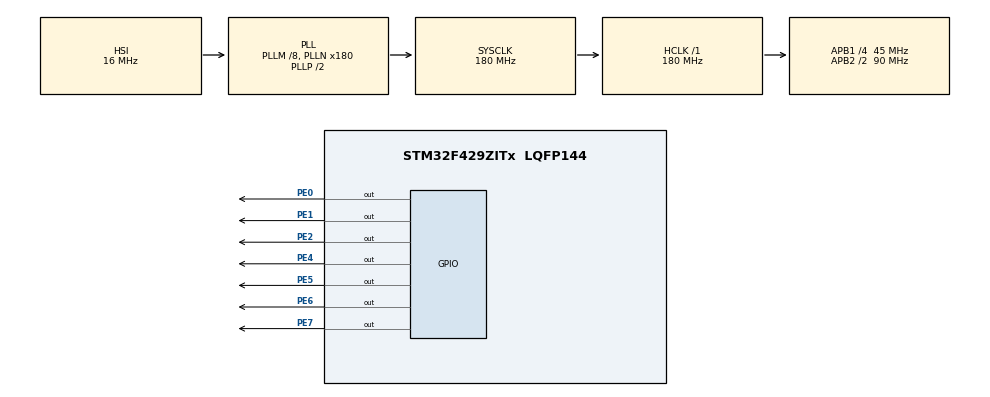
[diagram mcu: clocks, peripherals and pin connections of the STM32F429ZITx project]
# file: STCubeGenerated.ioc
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Mcu.Family=STM32F4
Mcu.Name=STM32F429ZITx
Mcu.Package=LQFP144
NVIC.PriorityGroup=NVIC_PRIORITYGROUP_4
PE0.Signal=GPIO_Output
PE1.Signal=GPIO_Output
PE2.Signal=GPIO_Output
PE4.Signal=GPIO_Output
PE5.Signal=GPIO_Output
PE6.Signal=GPIO_Output
PE7.Signal=GPIO_Output
PH0/OSC_IN.Mode=HSE-External-Oscillator
PH0/OSC_IN.Signal=RCC_OSC_IN
PH1/OSC_OUT.Mode=HSE-External-Oscillator
PH1/OSC_OUT.Signal=RCC_OSC_OUT
ProjectManager.HeapSize=0x200
ProjectManager.StackSize=0x400
ProjectManager.TargetToolchain=MDK-ARM V5
RCC.48MHZClocksFreq_Value=90000000
RCC.AHBFreq_Value=180000000
RCC.APB1CLKDivider=RCC_HCLK_DIV4
RCC.APB1Freq_Value=45000000
RCC.APB1TimFreq_Value=90000000
RCC.APB2CLKDivider=RCC_HCLK_DIV2
RCC.APB2Freq_Value=90000000
RCC.APB2TimFreq_Value=180000000
RCC.CortexFreq_Value=180000000
RCC.HCLKFreq_Value=180000000
RCC.HSE_VALUE=25000000
RCC.HSI_VALUE=16000000
RCC.LSE_VALUE=32768
RCC.PLLM=8
RCC.PLLN=180
RCC.SYSCLKFreq_VALUE=180000000
RCC.SYSCLKSource=RCC_SYSCLKSOURCE_PLLCLK
RCC.VCOOutputFreq_Value=360000000
board=custom

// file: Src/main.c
/* USER CODE BEGIN Header */
/**
  ******************************************************************************
  * @file           : main.c
  * @brief          : Main program body
  ******************************************************************************
  * @attention
  *
  * <h2><center>&copy; Copyright (c) 2019 STMicroelectronics.
  * All rights reserved.</center></h2>
  *
  * This software component is licensed by ST under BSD 3-Clause license,
  * the "License"; You may not use this file except in compliance with the
  * License. You may obtain a copy of the License at:
  *                        opensource.org/licenses/BSD-3-Clause
  *
  ******************************************************************************
  */
/* USER CODE END Header */

#include "main.h"

/* USER CODE BEGIN Includes */
#include "STM_LCD16X2.h"
/* USER CODE END Includes */

void SystemClock_Config(void);
static void MX_GPIO_Init(void);

int main(void)
{

  /* MCU Configuration--------------------------------------------------------*/

  /* Reset of all peripherals, Initializes the Flash interface and the Systick. */
  HAL_Init();

  /* Configure the system clock */
  SystemClock_Config();

  /* Initialize all configured peripherals */
  MX_GPIO_Init();
  /* USER CODE BEGIN 2 */
	LCD1602_Begin4BIT(RS_GPIO_Port, RS_Pin, E_Pin, D4_GPIO_Port, D4_Pin, D5_Pin, D6_Pin, D7_Pin);
	LCD1602_clear();
	LCD1602_print("I'm hungry!!");
	LCD1602_2ndLine();
	LCD1602_print("I wanna go home!");
  /* USER CODE END 2 */

  /* Infinite loop */
  while (1)
  {

  }
}

void SystemClock_Config(void)
{
  RCC_OscInitTypeDef RCC_OscInitStruct = {0};
  RCC_ClkInitTypeDef RCC_ClkInitStruct = {0};

  /** Configure the main internal regulator output voltage
  */
  __HAL_RCC_PWR_CLK_ENABLE();
  __HAL_PWR_VOLTAGESCALING_CONFIG(PWR_REGULATOR_VOLTAGE_SCALE1);
  /** Initializes the CPU, AHB and APB busses clocks
  */
  RCC_OscInitStruct.OscillatorType = RCC_OSCILLATORTYPE_HSI;
  RCC_OscInitStruct.HSIState = RCC_HSI_ON;
  RCC_OscInitStruct.HSICalibrationValue = RCC_HSICALIBRATION_DEFAULT;
  RCC_OscInitStruct.PLL.PLLState = RCC_PLL_ON;
  RCC_OscInitStruct.PLL.PLLSource = RCC_PLLSOURCE_HSI;
  RCC_OscInitStruct.PLL.PLLM = 8;
  RCC_OscInitStruct.PLL.PLLN = 180;
  RCC_OscInitStruct.PLL.PLLP = RCC_PLLP_DIV2;
  RCC_OscInitStruct.PLL.PLLQ = 4;
  if (HAL_RCC_OscConfig(&RCC_OscInitStruct) != HAL_OK)
  {
    Error_Handler();
  }
  /** Activate the Over-Drive mode
  */
  if (HAL_PWREx_EnableOverDrive() != HAL_OK)
  {
    Error_Handler();
  }
  /** Initializes the CPU, AHB and APB busses clocks
  */
  RCC_ClkInitStruct.ClockType = RCC_CLOCKTYPE_HCLK|RCC_CLOCKTYPE_SYSCLK
                              |RCC_CLOCKTYPE_PCLK1|RCC_CLOCKTYPE_PCLK2;
  RCC_ClkInitStruct.SYSCLKSource = RCC_SYSCLKSOURCE_PLLCLK;
  RCC_ClkInitStruct.AHBCLKDivider = RCC_SYSCLK_DIV1;
  RCC_ClkInitStruct.APB1CLKDivider = RCC_HCLK_DIV4;
  RCC_ClkInitStruct.APB2CLKDivider = RCC_HCLK_DIV2;

  if (HAL_RCC_ClockConfig(&RCC_ClkInitStruct, FLASH_LATENCY_5) != HAL_OK)
  {
    Error_Handler();
  }
}

static void MX_GPIO_Init(void)
{
  GPIO_InitTypeDef GPIO_InitStruct = {0};

  /* GPIO Ports Clock Enable */
  __HAL_RCC_GPIOE_CLK_ENABLE();
  __HAL_RCC_GPIOH_CLK_ENABLE();

  /*Configure GPIO pin Output Level */
  HAL_GPIO_WritePin(GPIOE, GPIO_PIN_2|GPIO_PIN_4|GPIO_PIN_5|GPIO_PIN_6
                          |GPIO_PIN_7|GPIO_PIN_0|GPIO_PIN_1, GPIO_PIN_RESET);

  /*Configure GPIO pins : PE2 PE4 PE5 PE6
                           PE7 PE0 PE1 */
  GPIO_InitStruct.Pin = GPIO_PIN_2|GPIO_PIN_4|GPIO_PIN_5|GPIO_PIN_6
                          |GPIO_PIN_7|GPIO_PIN_0|GPIO_PIN_1;
  GPIO_InitStruct.Mode = GPIO_MODE_OUTPUT_PP;
  GPIO_InitStruct.Pull = GPIO_NOPULL;
  GPIO_InitStruct.Speed = GPIO_SPEED_FREQ_LOW;
  HAL_GPIO_Init(GPIOE, &GPIO_InitStruct);

}

void Error_Handler(void)
{
}

/************************ (C) COPYRIGHT STMicroelectronics *****END OF FILE****/
